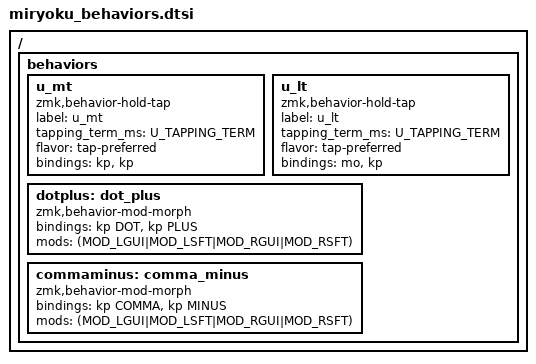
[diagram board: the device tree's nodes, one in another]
// Copyright 2022 Manna Harbour
// https://github.com/manna-harbour/miryoku

/ {
  behaviors {
    u_mt: u_mt {
      compatible = "zmk,behavior-hold-tap";
      label = "u_mt";
      #binding-cells = <2>;
      tapping_term_ms = <U_TAPPING_TERM>;
      flavor = "tap-preferred";
      bindings = <&kp>, <&kp>;
    };
    u_lt: u_lt {
      compatible = "zmk,behavior-hold-tap";
      label = "u_lt";
      #binding-cells = <2>;
      tapping_term_ms = <U_TAPPING_TERM>;
      flavor = "tap-preferred";
      bindings = <&mo>, <&kp>;
    };
    dotplus: dot_plus {
      compatible = "zmk,behavior-mod-morph";
      #binding-cells = <0>;
      bindings = <&kp DOT>, <&kp PLUS>;
      mods = <(MOD_LGUI|MOD_LSFT|MOD_RGUI|MOD_RSFT)>;
    };
    commaminus: comma_minus {
      compatible = "zmk,behavior-mod-morph";
      #binding-cells = <0>;
      bindings = <&kp COMMA>, <&kp MINUS>;
      mods = <(MOD_LGUI|MOD_LSFT|MOD_RGUI|MOD_RSFT)>;
    };
  };
};

// Aubrey additions: &dotplus, &commaminus
